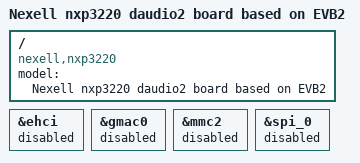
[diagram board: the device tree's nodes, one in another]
/*
 * (C) Copyright 2018 Nexell
 * JungHyun, Kim <jhkim@nexell.co.kr>
 *
 * SPDX-License-Identifier:      GPL-2.0+
 */

/dts-v1/;

#include "nxp3220-evb2-common.dtsi"

/ {
	model = "Nexell nxp3220 daudio2 board based on EVB2";
	compatible = "nexell,nxp3220";
};

&ehci {
	status = "disabled";
};

&gmac0 {
	status = "disabled";
};

&mmc2 {
	status = "disabled";
};

&spi_0 {
	status = "disabled";
};

